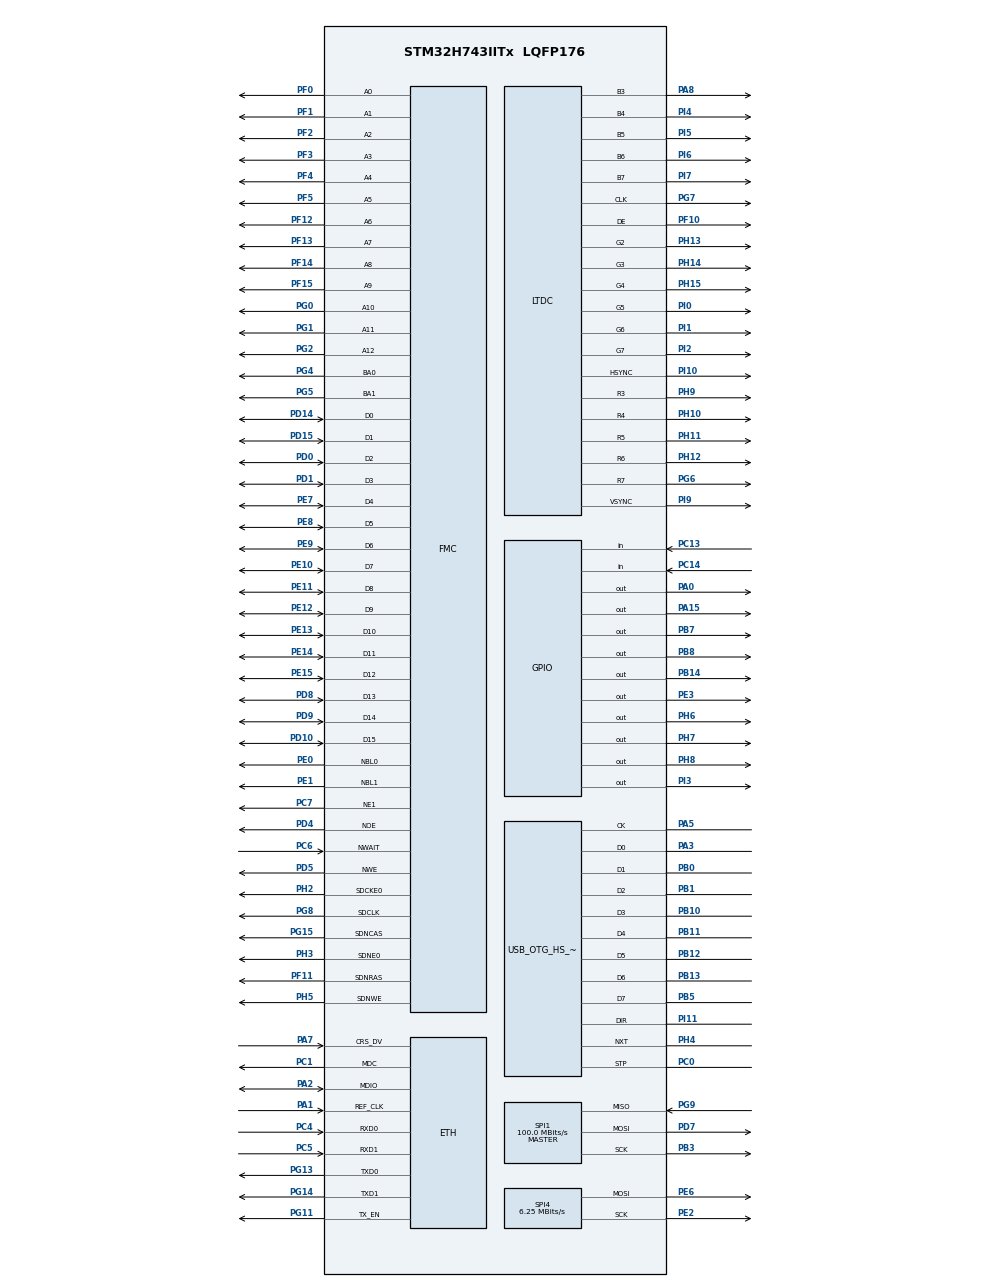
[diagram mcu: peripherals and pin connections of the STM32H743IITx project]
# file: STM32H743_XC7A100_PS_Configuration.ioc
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CORTEX_M7.AccessPermission_Spec=MPU_REGION_FULL_ACCESS
CORTEX_M7.BaseAddress_Spec=0xC0000000
CORTEX_M7.Enable_S-Cortex_Memory_Protection_Unit_Region1_Settings_S=__NULL
CORTEX_M7.IsBufferable_Spec=MPU_ACCESS_BUFFERABLE
CORTEX_M7.IsCacheable_Spec=MPU_ACCESS_CACHEABLE
CORTEX_M7.IsShareable_Spec=MPU_ACCESS_NOT_SHAREABLE
CORTEX_M7.Size_Spec=MPU_REGION_SIZE_4MB
CORTEX_M7.SubRegionDisable_Spec=0x0
CORTEX_M7.TypeExtField_Spec=MPU_TEX_LEVEL1
CORTEX_M7.default_mode_Activation=1
Dma.Request0=SPI4_TX
Dma.SPI4_TX.0.Direction=DMA_MEMORY_TO_PERIPH
Dma.SPI4_TX.0.EventEnable=DISABLE
Dma.SPI4_TX.0.FIFOMode=DMA_FIFOMODE_DISABLE
Dma.SPI4_TX.0.Instance=DMA1_Stream0
Dma.SPI4_TX.0.MemDataAlignment=DMA_MDATAALIGN_BYTE
Dma.SPI4_TX.0.MemInc=DMA_MINC_ENABLE
Dma.SPI4_TX.0.Mode=DMA_NORMAL
Dma.SPI4_TX.0.PeriphDataAlignment=DMA_PDATAALIGN_BYTE
Dma.SPI4_TX.0.PeriphInc=DMA_PINC_DISABLE
Dma.SPI4_TX.0.Polarity=HAL_DMAMUX_REQ_GEN_RISING
Dma.SPI4_TX.0.Priority=DMA_PRIORITY_LOW
Dma.SPI4_TX.0.RequestNumber=1
Dma.SPI4_TX.0.SignalID=NONE
Dma.SPI4_TX.0.SyncEnable=DISABLE
Dma.SPI4_TX.0.SyncPolarity=HAL_DMAMUX_SYNC_NO_EVENT
Dma.SPI4_TX.0.SyncRequestNumber=1
Dma.SPI4_TX.0.SyncSignalID=NONE
ETH.MediaInterface=HAL_ETH_RMII_MODE
FMC.CASLatency1=FMC_SDRAM_CAS_LATENCY_3
FMC.ColumnBitsNumber1=FMC_SDRAM_COLUMN_BITS_NUM_9
FMC.DataSetupTime1=10
FMC.ExitSelfRefreshDelay1=8
FMC.LoadToActiveDelay1=2
FMC.RCDDelay1=2
FMC.RPDelay1=2
FMC.ReadBurst1=FMC_SDRAM_RBURST_ENABLE
FMC.ReadPipeDelay1=FMC_SDRAM_RPIPE_DELAY_1
FMC.RowCycleDelay1=6
FMC.SDClockPeriod1=FMC_SDRAM_CLOCK_PERIOD_2
FMC.SelfRefreshTime1=6
FMC.WriteFifo1=FMC_WRITE_FIFO_DISABLE
FMC.WriteFifo2=FMC_WRITE_FIFO_DISABLE
FMC.WriteFifo3=FMC_WRITE_FIFO_DISABLE
FMC.WriteFifo4=FMC_WRITE_FIFO_DISABLE
FMC.WriteOperation1=FMC_WRITE_OPERATION_ENABLE
FMC.WriteRecoveryTime1=4
FREERTOS.Tasks01=FPGAConfigTask,0,2048,FPGAConfigDefaultTask,As weak,NULL,Dynamic,NULL,NULL;ewWinTask,-3,8192,ewWinDefaultTask,As weak,NULL,Dynamic,NULL,NULL;mousekeyTask,-3,1024,mousekeyDefaultTask,As weak,NULL,Dynamic,NULL,NULL;ETH,-3,2048,ETHDefaultTask,As weak,NULL,Dynamic,NULL,NULL
FREERTOS.configTOTAL_HEAP_SIZE=65535
LTDC.ActiveH=800
LTDC.ActiveW=480
LTDC.DEPolarity=LTDC_DEPOLARITY_AH
LTDC.HBP=1
LTDC.HFP=1
LTDC.HSPolarity=LTDC_HSPOLARITY_AH
LTDC.HSync=1
LTDC.PCPolarity=LTDC_PCPOLARITY_IIPC
LTDC.VBP=1
LTDC.VFP=1
LTDC.VSPolarity=LTDC_VSPOLARITY_AH
LTDC.VSync=1
LWIP.BSP.number=1
LWIP.GATEWAY_ADDRESS=192.168.100.001
LWIP.IP_ADDRESS=192.168.100.050
LWIP.LWIP_DHCP=0
LWIP.NETMASK_ADDRESS=255.255.255.000
LWIP.Version=v2.1.2_Cube
LWIP0.BSP.STBoard=false
LWIP0.BSP.api=BSP_COMPONENT_DRIVER
LWIP0.BSP.component=LAN8742
LWIP0.BSP.instance=LAN8742
LWIP0.BSP.name=Driver_PHY
LWIP0.BSP.semaphore=S_LAN8742
LWIP0.BSP.solution=LAN8742
Mcu.Family=STM32H7
Mcu.Name=STM32H743IITx
Mcu.Package=LQFP176
NVIC.DMA1_Stream0_IRQn=true\:5\:0\:false\:false\:true\:true\:false\:true\:true
NVIC.DMA2D_IRQn=true\:5\:0\:false\:false\:true\:true\:true\:true\:true
NVIC.LTDC_IRQn=true\:5\:0\:false\:false\:true\:true\:true\:true\:true
NVIC.OTG_HS_IRQn=true\:5\:0\:false\:false\:true\:true\:false\:true\:true
NVIC.PriorityGroup=NVIC_PRIORITYGROUP_4
NVIC.SPI4_IRQn=true\:5\:0\:false\:false\:true\:true\:false\:true\:true
PA0.Signal=GPIO_Output
PA1.GPIO_Speed=GPIO_SPEED_FREQ_VERY_HIGH
PA1.Mode=RMII
PA1.Signal=ETH_REF_CLK
PA13\ (JTMS/SWDIO).Mode=Serial_Wire
PA13\ (JTMS/SWDIO).Signal=DEBUG_JTMS-SWDIO
PA14\ (JTCK/SWCLK).Mode=Serial_Wire
PA14\ (JTCK/SWCLK).Signal=DEBUG_JTCK-SWCLK
PA15\ (JTDI).PinState=GPIO_PIN_SET
PA15\ (JTDI).Signal=GPIO_Output
PA2.GPIO_Speed=GPIO_SPEED_FREQ_VERY_HIGH
PA2.Mode=RMII
PA2.Signal=ETH_MDIO
PA3.Mode=Device_HS
PA3.Signal=USB_OTG_HS_ULPI_D0
PA5.Mode=Device_HS
PA5.Signal=USB_OTG_HS_ULPI_CK
PA7.GPIO_Speed=GPIO_SPEED_FREQ_VERY_HIGH
PA7.Mode=RMII
PA7.Signal=ETH_CRS_DV
PA8.GPIO_Speed=GPIO_SPEED_FREQ_VERY_HIGH
PA8.Mode=RGB565
PA8.Signal=LTDC_B3
PB0.Mode=Device_HS
PB0.Signal=USB_OTG_HS_ULPI_D1
PB1.Mode=Device_HS
PB1.Signal=USB_OTG_HS_ULPI_D2
PB10.Mode=Device_HS
PB10.Signal=USB_OTG_HS_ULPI_D3
PB11.Mode=Device_HS
PB11.Signal=USB_OTG_HS_ULPI_D4
PB12.Mode=Device_HS
PB12.Signal=USB_OTG_HS_ULPI_D5
PB13.Mode=Device_HS
PB13.Signal=USB_OTG_HS_ULPI_D6
PB14.Signal=GPIO_Output
PB3\ (JTDO/TRACESWO).Mode=Full_Duplex_Master
PB3\ (JTDO/TRACESWO).Signal=SPI1_SCK
PB5.Mode=Device_HS
PB5.Signal=USB_OTG_HS_ULPI_D7
PB7.GPIO_ModeDefaultOutputPP=GPIO_MODE_OUTPUT_OD
PB7.GPIO_PuPd=GPIO_NOPULL
PB7.Signal=GPIO_Output
PB8.GPIO_ModeDefaultOutputPP=GPIO_MODE_OUTPUT_OD
PB8.GPIO_PuPd=GPIO_NOPULL
PB8.Signal=GPIO_Output
PC0.Mode=Device_HS
PC0.Signal=USB_OTG_HS_ULPI_STP
PC1.GPIO_Speed=GPIO_SPEED_FREQ_VERY_HIGH
PC1.Mode=RMII
PC1.Signal=ETH_MDC
PC13.GPIO_PuPd=GPIO_PULLUP
PC13.Signal=GPIO_Input
PC14-OSC32_IN\ (OSC32_IN).GPIO_PuPd=GPIO_PULLUP
PC14-OSC32_IN\ (OSC32_IN).Signal=GPIO_Input
PC4.GPIO_Speed=GPIO_SPEED_FREQ_VERY_HIGH
PC4.Mode=RMII
PC4.Signal=ETH_RXD0
PC5.GPIO_Speed=GPIO_SPEED_FREQ_VERY_HIGH
PC5.Mode=RMII
PC5.Signal=ETH_RXD1
PC6.Signal=FMC_NWAIT
PC7.Mode=NorPsramChipSelect1_1
PC7.Signal=FMC_NE1
PD0.GPIO_PuPd=GPIO_PULLUP
PD0.Signal=FMC_D2_DA2
PD1.GPIO_PuPd=GPIO_PULLUP
PD1.Signal=FMC_D3_DA3
PD10.GPIO_PuPd=GPIO_PULLUP
PD10.Signal=FMC_D15_DA15
PD14.GPIO_PuPd=GPIO_PULLUP
PD14.Signal=FMC_D0_DA0
PD15.GPIO_PuPd=GPIO_PULLUP
PD15.Signal=FMC_D1_DA1
PD4.Signal=FMC_NOE
PD5.Signal=FMC_NWE
PD7.Mode=Full_Duplex_Master
PD7.Signal=SPI1_MOSI
PD8.GPIO_PuPd=GPIO_PULLUP
PD8.Signal=FMC_D13_DA13
PD9.GPIO_PuPd=GPIO_PULLUP
PD9.Signal=FMC_D14_DA14
PE0.GPIO_PuPd=GPIO_PULLUP
PE0.Signal=FMC_NBL0
PE1.GPIO_PuPd=GPIO_PULLUP
PE1.Signal=FMC_NBL1
PE10.GPIO_PuPd=GPIO_PULLUP
PE10.Signal=FMC_D7_DA7
PE11.GPIO_PuPd=GPIO_PULLUP
PE11.Signal=FMC_D8_DA8
PE12.GPIO_PuPd=GPIO_PULLUP
PE12.Signal=FMC_D9_DA9
PE13.GPIO_PuPd=GPIO_PULLUP
PE13.Signal=FMC_D10_DA10
PE14.GPIO_PuPd=GPIO_PULLUP
PE14.Signal=FMC_D11_DA11
PE15.GPIO_PuPd=GPIO_PULLUP
PE15.Signal=FMC_D12_DA12
PE2.GPIO_Speed=GPIO_SPEED_FREQ_HIGH
PE2.Mode=TX_Only_Simplex_Unidirect_Master
PE2.Signal=SPI4_SCK
PE3.Signal=GPIO_Output
PE6.GPIO_Speed=GPIO_SPEED_FREQ_HIGH
PE6.Mode=TX_Only_Simplex_Unidirect_Master
PE6.Signal=SPI4_MOSI
PE7.GPIO_PuPd=GPIO_PULLUP
PE7.Signal=FMC_D4_DA4
PE8.GPIO_PuPd=GPIO_PULLUP
PE8.Signal=FMC_D5_DA5
PE9.GPIO_PuPd=GPIO_PULLUP
PE9.Signal=FMC_D6_DA6
PF0.GPIO_PuPd=GPIO_PULLUP
PF0.Signal=FMC_A0
PF1.GPIO_PuPd=GPIO_PULLUP
PF1.Signal=FMC_A1
PF10.GPIO_Speed=GPIO_SPEED_FREQ_VERY_HIGH
PF10.Mode=RGB565
PF10.Signal=LTDC_DE
PF11.GPIO_PuPd=GPIO_PULLUP
PF11.Signal=FMC_SDNRAS
PF12.GPIO_PuPd=GPIO_PULLUP
PF12.Signal=FMC_A6
PF13.GPIO_PuPd=GPIO_PULLUP
PF13.Signal=FMC_A7
PF14.GPIO_PuPd=GPIO_PULLUP
PF14.Signal=FMC_A8
PF15.GPIO_PuPd=GPIO_PULLUP
PF15.Signal=FMC_A9
PF2.GPIO_PuPd=GPIO_PULLUP
PF2.Signal=FMC_A2
PF3.GPIO_PuPd=GPIO_PULLUP
PF3.Signal=FMC_A3
PF4.GPIO_PuPd=GPIO_PULLUP
PF4.Signal=FMC_A4
PF5.GPIO_PuPd=GPIO_PULLUP
PF5.Signal=FMC_A5
PG0.GPIO_PuPd=GPIO_PULLUP
PG0.Signal=FMC_A10
PG1.GPIO_PuPd=GPIO_PULLUP
PG1.Signal=FMC_A11
PG11.GPIO_Speed=GPIO_SPEED_FREQ_VERY_HIGH
PG11.Mode=RMII
PG11.Signal=ETH_TX_EN
PG13.GPIO_Speed=GPIO_SPEED_FREQ_VERY_HIGH
PG13.Mode=RMII
PG13.Signal=ETH_TXD0
PG14.GPIO_Speed=GPIO_SPEED_FREQ_VERY_HIGH
PG14.Mode=RMII
PG14.Signal=ETH_TXD1
PG15.GPIO_PuPd=GPIO_PULLUP
PG15.Signal=FMC_SDNCAS
PG2.GPIO_PuPd=GPIO_PULLUP
PG2.Signal=FMC_A12
PG4.GPIO_PuPd=GPIO_PULLUP
PG4.Signal=FMC_A14_BA0
PG5.GPIO_PuPd=GPIO_PULLUP
PG5.Signal=FMC_A15_BA1
PG6.GPIO_Speed=GPIO_SPEED_FREQ_VERY_HIGH
PG6.Mode=RGB565
PG6.Signal=LTDC_R7
PG7.GPIO_Speed=GPIO_SPEED_FREQ_VERY_HIGH
PG7.Mode=RGB565
PG7.Signal=LTDC_CLK
PG8.GPIO_PuPd=GPIO_PULLUP
PG8.Signal=FMC_SDCLK
PG9.Mode=Full_Duplex_Master
PG9.Signal=SPI1_MISO
PH0-OSC_IN\ (PH0).Mode=HSE-External-Clock-Source
PH0-OSC_IN\ (PH0).Signal=RCC_OSC_IN
PH10.GPIO_Speed=GPIO_SPEED_FREQ_VERY_HIGH
PH10.Mode=RGB565
PH10.Signal=LTDC_R4
PH11.GPIO_Speed=GPIO_SPEED_FREQ_VERY_HIGH
PH11.Mode=RGB565
PH11.Signal=LTDC_R5
PH12.GPIO_Speed=GPIO_SPEED_FREQ_VERY_HIGH
PH12.Mode=RGB565
PH12.Signal=LTDC_R6
PH13.GPIO_Speed=GPIO_SPEED_FREQ_VERY_HIGH
PH13.Mode=RGB565
PH13.Signal=LTDC_G2
PH14.GPIO_Speed=GPIO_SPEED_FREQ_VERY_HIGH
PH14.Mode=RGB565
PH14.Signal=LTDC_G3
PH15.GPIO_Speed=GPIO_SPEED_FREQ_VERY_HIGH
PH15.Mode=RGB565
PH15.Signal=LTDC_G4
PH2.GPIO_PuPd=GPIO_PULLUP
PH2.Mode=SdramChipSelect1_1
PH2.Signal=FMC_SDCKE0
PH3.GPIO_PuPd=GPIO_PULLUP
PH3.Mode=SdramChipSelect1_1
PH3.Signal=FMC_SDNE0
PH4.Mode=Device_HS
PH4.Signal=USB_OTG_HS_ULPI_NXT
PH5.GPIO_PuPd=GPIO_PULLUP
PH5.Signal=FMC_SDNWE
PH6.GPIO_Speed=GPIO_SPEED_FREQ_VERY_HIGH
PH6.Signal=GPIO_Output
PH7.GPIO_Speed=GPIO_SPEED_FREQ_VERY_HIGH
PH7.Signal=GPIO_Output
PH8.GPIO_Speed=GPIO_SPEED_FREQ_VERY_HIGH
PH8.Signal=GPIO_Output
PH9.GPIO_Speed=GPIO_SPEED_FREQ_VERY_HIGH
PH9.Mode=RGB565
PH9.Signal=LTDC_R3
PI0.GPIO_Speed=GPIO_SPEED_FREQ_VERY_HIGH
PI0.Mode=RGB565
PI0.Signal=LTDC_G5
PI1.GPIO_Speed=GPIO_SPEED_FREQ_VERY_HIGH
PI1.Mode=RGB565
PI1.Signal=LTDC_G6
PI10.GPIO_Speed=GPIO_SPEED_FREQ_VERY_HIGH
PI10.Mode=RGB565
PI10.Signal=LTDC_HSYNC
PI11.Mode=Device_HS
PI11.Signal=USB_OTG_HS_ULPI_DIR
PI2.GPIO_Speed=GPIO_SPEED_FREQ_VERY_HIGH
PI2.Mode=RGB565
PI2.Signal=LTDC_G7
PI3.PinState=GPIO_PIN_SET
PI3.Signal=GPIO_Output
PI4.GPIO_Speed=GPIO_SPEED_FREQ_VERY_HIGH
PI4.Mode=RGB565
PI4.Signal=LTDC_B4
PI5.GPIO_Speed=GPIO_SPEED_FREQ_VERY_HIGH
PI5.Mode=RGB565
PI5.Signal=LTDC_B5
PI6.GPIO_Speed=GPIO_SPEED_FREQ_VERY_HIGH
PI6.Mode=RGB565
PI6.Signal=LTDC_B6
PI7.GPIO_Speed=GPIO_SPEED_FREQ_VERY_HIGH
PI7.Mode=RGB565
PI7.Signal=LTDC_B7
PI9.GPIO_Speed=GPIO_SPEED_FREQ_VERY_HIGH
PI9.Mode=RGB565
PI9.Signal=LTDC_VSYNC
ProjectManager.HeapSize=0x200
ProjectManager.StackSize=0x400
ProjectManager.TargetToolchain=MDK-ARM V5.32
RCC.ADCFreq_Value=200000000
RCC.APB1Freq_Value=100000000
RCC.APB2Freq_Value=100000000
RCC.APB3Freq_Value=100000000
RCC.APB4Freq_Value=100000000
RCC.CortexFreq_Value=400000000
RCC.D1PPRE=RCC_APB3_DIV2
RCC.D2PPRE1=RCC_APB1_DIV2
RCC.D2PPRE2=RCC_APB2_DIV2
RCC.D3PPRE=RCC_APB4_DIV2
RCC.DIVM1=5
RCC.DIVM2=5
RCC.DIVM3=5
RCC.DIVN1=160
RCC.DIVN2=80
RCC.DIVN3=88
RCC.DIVQ1=4
RCC.DIVQ3=4
RCC.DIVR3=18
RCC.FMCCLockSelection=RCC_FMCCLKSOURCE_PLL
RCC.HCLKFreq_Value=200000000
RCC.HPRE=RCC_HCLK_DIV2
RCC.PLL2FRACN=0
RCC.PLL3FRACN=0
RCC.PLLFRACN=0
RCC.PLLSourceVirtual=RCC_PLLSOURCE_HSE
RCC.SYSCLKFreq_VALUE=400000000
RCC.SYSCLKSource=RCC_SYSCLKSOURCE_PLLCLK
RCC.USBCLockSelection=RCC_USBCLKSOURCE_HSI48
RCC.USBFreq_Value=48000000
SH.FMC_A0.0=FMC_A0,13b-sda1
SH.FMC_A0.1=FMC_A0,1b-a1
SH.FMC_A1.0=FMC_A1,13b-sda1
SH.FMC_A10.0=FMC_A10,13b-sda1
SH.FMC_A11.0=FMC_A11,13b-sda1
SH.FMC_A12.0=FMC_A12,13b-sda1
SH.FMC_A14_BA0.0=FMC_BA0,FourSdramBanks1
SH.FMC_A15_BA1.0=FMC_BA1,FourSdramBanks1
SH.FMC_A2.0=FMC_A2,13b-sda1
SH.FMC_A3.0=FMC_A3,13b-sda1
SH.FMC_A4.0=FMC_A4,13b-sda1
SH.FMC_A5.0=FMC_A5,13b-sda1
SH.FMC_A6.0=FMC_A6,13b-sda1
SH.FMC_A7.0=FMC_A7,13b-sda1
SH.FMC_A8.0=FMC_A8,13b-sda1
SH.FMC_A9.0=FMC_A9,13b-sda1
SH.FMC_D0_DA0.0=FMC_D0,sd-16b-d1
SH.FMC_D0_DA0.1=FMC_D0,16b-d1
SH.FMC_D10_DA10.0=FMC_D10,sd-16b-d1
SH.FMC_D10_DA10.1=FMC_D10,16b-d1
SH.FMC_D11_DA11.0=FMC_D11,sd-16b-d1
SH.FMC_D11_DA11.1=FMC_D11,16b-d1
SH.FMC_D12_DA12.0=FMC_D12,sd-16b-d1
SH.FMC_D12_DA12.1=FMC_D12,16b-d1
SH.FMC_D13_DA13.0=FMC_D13,sd-16b-d1
SH.FMC_D13_DA13.1=FMC_D13,16b-d1
SH.FMC_D14_DA14.0=FMC_D14,sd-16b-d1
SH.FMC_D14_DA14.1=FMC_D14,16b-d1
SH.FMC_D15_DA15.0=FMC_D15,sd-16b-d1
SH.FMC_D15_DA15.1=FMC_D15,16b-d1
SH.FMC_D1_DA1.0=FMC_D1,sd-16b-d1
SH.FMC_D1_DA1.1=FMC_D1,16b-d1
SH.FMC_D2_DA2.0=FMC_D2,sd-16b-d1
SH.FMC_D2_DA2.1=FMC_D2,16b-d1
SH.FMC_D3_DA3.0=FMC_D3,sd-16b-d1
SH.FMC_D3_DA3.1=FMC_D3,16b-d1
SH.FMC_D4_DA4.0=FMC_D4,sd-16b-d1
SH.FMC_D4_DA4.1=FMC_D4,16b-d1
SH.FMC_D5_DA5.0=FMC_D5,sd-16b-d1
SH.FMC_D5_DA5.1=FMC_D5,16b-d1
SH.FMC_D6_DA6.0=FMC_D6,sd-16b-d1
SH.FMC_D6_DA6.1=FMC_D6,16b-d1
SH.FMC_D7_DA7.0=FMC_D7,sd-16b-d1
SH.FMC_D7_DA7.1=FMC_D7,16b-d1
SH.FMC_D8_DA8.0=FMC_D8,sd-16b-d1
SH.FMC_D8_DA8.1=FMC_D8,16b-d1
SH.FMC_D9_DA9.0=FMC_D9,sd-16b-d1
SH.FMC_D9_DA9.1=FMC_D9,16b-d1
SH.FMC_NBL0.0=FMC_NBL0,Sd2ByteEnable1
SH.FMC_NBL1.0=FMC_NBL1,Sd2ByteEnable1
SH.FMC_NOE.0=FMC_NOE,Sram1
SH.FMC_NWAIT.0=FMC_NWAIT,AsynchronousWait1
SH.FMC_NWE.0=FMC_NWE,Sram1
SH.FMC_SDCLK.0=FMC_SDCLK,13b-sda1
SH.FMC_SDNCAS.0=FMC_SDNCAS,13b-sda1
SH.FMC_SDNRAS.0=FMC_SDNRAS,13b-sda1
SH.FMC_SDNWE.0=FMC_SDNWE,13b-sda1
SPI1.CalculateBaudRate=100.0 MBits/s
SPI1.Direction=SPI_DIRECTION_2LINES
SPI1.Mode=SPI_MODE_MASTER
SPI1.VirtualType=VM_MASTER
SPI4.BaudRatePrescaler=SPI_BAUDRATEPRESCALER_16
SPI4.CLKPhase=SPI_PHASE_2EDGE
SPI4.CLKPolarity=SPI_POLARITY_HIGH
SPI4.CalculateBaudRate=6.25 MBits/s
SPI4.DataSize=SPI_DATASIZE_8BIT
SPI4.Direction=SPI_DIRECTION_2LINES_TXONLY
SPI4.Mode=SPI_MODE_MASTER
SPI4.NSSPMode=SPI_NSS_PULSE_DISABLE
SPI4.VirtualType=VM_MASTER
USB_DEVICE.CLASS_NAME_HS=CDC
USB_DEVICE.VirtualMode-CDC_HS=Cdc
USB_DEVICE.VirtualModeHS=Cdc_HS
USB_OTG_HS.VirtualMode-Device_HS=Device_HS
VP_DMA2D_VS_DMA2D.Mode=DMA2D_Activate
VP_FREERTOS_VS_CMSIS_V1.Mode=CMSIS_V1
VP_LWIP_VS_Enabled.Mode=Enabled
VP_MEMORYMAP_VS_MEMORYMAP.Mode=CurAppReg
VP_USB_DEVICE_VS_USB_DEVICE_CDC_HS.Mode=CDC_HS
board=custom

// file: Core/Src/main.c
/* USER CODE BEGIN Header */
/**
  ******************************************************************************
  * @file           : main.c
  * @brief          : Main program body
  ******************************************************************************
  * @attention
  *
  * Copyright (c) 2026 STMicroelectronics.
  * All rights reserved.
  *
  * This software is licensed under terms that can be found in the LICENSE file
  * in the root directory of this software component.
  * If no LICENSE file comes with this software, it is provided AS-IS.
  *
  ******************************************************************************
  */
/* USER CODE END Header */
#include "main.h"
#include "cmsis_os.h"
#include "dma.h"
#include "dma2d.h"
#include "ltdc.h"
#include "lwip.h"
#include "memorymap.h"
#include "spi.h"
#include "usb_device.h"
#include "gpio.h"
#include "fmc.h"

/* USER CODE BEGIN Includes */
#include "sdram.h"
#include "bsp_lcd_rgb.h"
#include "bsp_dwt.h"
#include "bsp_led.h"

extern volatile uint8_t g_sdram_ready;
/* USER CODE END Includes */

/* USER CODE BEGIN PD */
#define CONFIGURATION_MODE 0  //1-Slave Serial 0-JTAG
#define UI_EARLY_LCD_DIAG 0U
#define LATTICE_SINGLE_WIRE_TEST 0U
/* USER CODE END PD */

/* USER CODE BEGIN PV */
volatile uint8_t test = 0U;

/* USER CODE END PV */

void SystemClock_Config(void);
static void MPU_Config(void);
void MX_FREERTOS_Init(void);
/* USER CODE BEGIN PFP */
static void CPU_CACHE_Enable(void);
static void UI_CustomPlatformInit(void);
static void LatticeSingleWireTestInit(void);
static void LatticeSingleWireTestRun(void);

/* USER CODE END PFP */

/* USER CODE BEGIN 0 */

static void UI_EarlyFramebufferInit(void)
{
  uint32_t i;
  uint16_t *p_logic = (uint16_t *)0xC0000000U;
  uint16_t *p0 = (uint16_t *)0xC0200000U;
  uint16_t *p1 = (uint16_t *)0xC0300000U;
  const uint32_t logic_pixels = 2U * 800U * 480U;
  const uint32_t phys_pixels  = 480U * 800U;

  for (i = 0U; i < logic_pixels; i++)
  {
    p_logic[i] = 0U;
  }

  for (i = 0U; i < phys_pixels; i++)
  {
    p0[i] = 0U;
    p1[i] = 0U;
  }

  SCB_CleanDCache_by_Addr((uint32_t *)0xC0000000U, logic_pixels * 2U);
  SCB_CleanDCache_by_Addr((uint32_t *)0xC0200000U, phys_pixels * 2U);
  SCB_CleanDCache_by_Addr((uint32_t *)0xC0300000U, phys_pixels * 2U);
}

static void UI_CustomPlatformInit(void)
{
  /* FMC base init is generated by CubeMX; SDRAM command sequence is not. */
  SDRAM_Init_Sequence();
  g_sdram_ready = 1U;
}

static void LatticeSingleWireTestInit(void)
{
  GPIO_InitTypeDef GPIO_InitStruct = {0};

  HAL_GPIO_WritePin(GPIOB, GPIO_PIN_3, GPIO_PIN_RESET);

  GPIO_InitStruct.Pin = GPIO_PIN_3;
  GPIO_InitStruct.Mode = GPIO_MODE_OUTPUT_PP;
  GPIO_InitStruct.Pull = GPIO_NOPULL;
  GPIO_InitStruct.Speed = GPIO_SPEED_FREQ_LOW;
  HAL_GPIO_Init(GPIOB, &GPIO_InitStruct);

  GPIO_InitStruct.Pin = GPIO_PIN_9;
  GPIO_InitStruct.Mode = GPIO_MODE_INPUT;
  GPIO_InitStruct.Pull = GPIO_NOPULL;
  HAL_GPIO_Init(GPIOG, &GPIO_InitStruct);

  test = (uint8_t)HAL_GPIO_ReadPin(GPIOG, GPIO_PIN_9);
}

static void LatticeSingleWireTestRun(void)
{
  for (;;)
  {
    test = (uint8_t)HAL_GPIO_ReadPin(GPIOG, GPIO_PIN_9);
    HAL_Delay(1);
  }
}

/* USER CODE END 0 */

int main(void)
{

  /* MPU Configuration--------------------------------------------------------*/
  MPU_Config();

  /* MCU Configuration--------------------------------------------------------*/

  /* Reset of all peripherals, Initializes the Flash interface and the Systick. */
  HAL_Init();

  /* USER CODE BEGIN Init */
  CPU_CACHE_Enable();

  /* USER CODE END Init */

  /* Configure the system clock */
  SystemClock_Config();

  /* Initialize all configured peripherals */
  MX_GPIO_Init();
  MX_DMA_Init();
  MX_FMC_Init();
  MX_SPI4_Init();
  MX_DMA2D_Init();
  MX_LTDC_Init();
  MX_SPI1_Init();
  /* USER CODE BEGIN 2 */
  UI_CustomPlatformInit();
#if (UI_EARLY_LCD_DIAG == 1U)
//  UI_EarlyFramebufferInit();
//  LCD_RGB_Init();
//  if (LTDC_Layer1->CFBAR != 0xC0200000U)
//  {
//    LTDC_Layer1->CFBAR = 0xC0200000U;
//    LTDC->SRCR = LTDC_SRCR_IMR;
//  }
//  LCD_RGB_BacklightOn();
//  LCD_RGB_Fill(0xFFFFU);
//  bsp_LedOn(4);
  for (;;)
  {
		HAL_GPIO_TogglePin(GPIOA,GPIO_PIN_0);
    HAL_Delay(500);
  }
#endif

  /* USER CODE END 2 */

  /* Call init function for freertos objects (in cmsis_os2.c) */
  MX_FREERTOS_Init();

  /* Start scheduler */
  osKernelStart();

  /* We should never get here as control is now taken by the scheduler */

  /* Infinite loop */
  while (1)
  {

  }
}

void SystemClock_Config(void)
{
  RCC_OscInitTypeDef RCC_OscInitStruct = {0};
  RCC_ClkInitTypeDef RCC_ClkInitStruct = {0};

  /** Supply configuration update enable
  */
  HAL_PWREx_ConfigSupply(PWR_LDO_SUPPLY);

  /** Configure the main internal regulator output voltage
  */
  __HAL_PWR_VOLTAGESCALING_CONFIG(PWR_REGULATOR_VOLTAGE_SCALE1);

  while(!__HAL_PWR_GET_FLAG(PWR_FLAG_VOSRDY)) {}

  /** Initializes the RCC Oscillators according to the specified parameters
  * in the RCC_OscInitTypeDef structure.
  */
  RCC_OscInitStruct.OscillatorType = RCC_OSCILLATORTYPE_HSI48|RCC_OSCILLATORTYPE_HSE;
  RCC_OscInitStruct.HSEState = RCC_HSE_BYPASS;
  RCC_OscInitStruct.HSI48State = RCC_HSI48_ON;
  RCC_OscInitStruct.PLL.PLLState = RCC_PLL_ON;
  RCC_OscInitStruct.PLL.PLLSource = RCC_PLLSOURCE_HSE;
  RCC_OscInitStruct.PLL.PLLM = 5;
  RCC_OscInitStruct.PLL.PLLN = 160;
  RCC_OscInitStruct.PLL.PLLP = 2;
  RCC_OscInitStruct.PLL.PLLQ = 4;
  RCC_OscInitStruct.PLL.PLLR = 2;
  RCC_OscInitStruct.PLL.PLLRGE = RCC_PLL1VCIRANGE_2;
  RCC_OscInitStruct.PLL.PLLVCOSEL = RCC_PLL1VCOWIDE;
  RCC_OscInitStruct.PLL.PLLFRACN = 0;
  if (HAL_RCC_OscConfig(&RCC_OscInitStruct) != HAL_OK)
  {
    Error_Handler();
  }

  /** Initializes the CPU, AHB and APB buses clocks
  */
  RCC_ClkInitStruct.ClockType = RCC_CLOCKTYPE_HCLK|RCC_CLOCKTYPE_SYSCLK
                              |RCC_CLOCKTYPE_PCLK1|RCC_CLOCKTYPE_PCLK2
                              |RCC_CLOCKTYPE_D3PCLK1|RCC_CLOCKTYPE_D1PCLK1;
  RCC_ClkInitStruct.SYSCLKSource = RCC_SYSCLKSOURCE_PLLCLK;
  RCC_ClkInitStruct.SYSCLKDivider = RCC_SYSCLK_DIV1;
  RCC_ClkInitStruct.AHBCLKDivider = RCC_HCLK_DIV2;
  RCC_ClkInitStruct.APB3CLKDivider = RCC_APB3_DIV2;
  RCC_ClkInitStruct.APB1CLKDivider = RCC_APB1_DIV2;
  RCC_ClkInitStruct.APB2CLKDivider = RCC_APB2_DIV2;
  RCC_ClkInitStruct.APB4CLKDivider = RCC_APB4_DIV2;

  if (HAL_RCC_ClockConfig(&RCC_ClkInitStruct, FLASH_LATENCY_2) != HAL_OK)
  {
    Error_Handler();
  }
}

/* USER CODE BEGIN 4 */
static void CPU_CACHE_Enable(void)
{
  SCB_EnableICache();
  SCB_EnableDCache();
  SCB->CCR &= ~(uint32_t)SCB_CCR_UNALIGN_TRP_Msk;
  __DSB();
  __ISB();
}
/* USER CODE END 4 */

 /* MPU Configuration */

void MPU_Config(void)
{
  MPU_Region_InitTypeDef MPU_InitStruct = {0};

  /* Disables the MPU */
  HAL_MPU_Disable();

  /** Initializes and configures the Region and the memory to be protected
  */
  MPU_InitStruct.Enable = MPU_REGION_ENABLE;
  MPU_InitStruct.Number = MPU_REGION_NUMBER0;
  MPU_InitStruct.BaseAddress = 0xC0000000;
  MPU_InitStruct.Size = MPU_REGION_SIZE_4MB;
  MPU_InitStruct.SubRegionDisable = 0x0;
  MPU_InitStruct.TypeExtField = MPU_TEX_LEVEL1;
  MPU_InitStruct.AccessPermission = MPU_REGION_FULL_ACCESS;
  MPU_InitStruct.DisableExec = MPU_INSTRUCTION_ACCESS_DISABLE;
  MPU_InitStruct.IsShareable = MPU_ACCESS_NOT_SHAREABLE;
  MPU_InitStruct.IsCacheable = MPU_ACCESS_CACHEABLE;
  MPU_InitStruct.IsBufferable = MPU_ACCESS_BUFFERABLE;

  HAL_MPU_ConfigRegion(&MPU_InitStruct);
  /* Enables the MPU */
  HAL_MPU_Enable(MPU_PRIVILEGED_DEFAULT);

}

void Error_Handler(void)
{
  __disable_irq();
  while (1)
  {
  }
}

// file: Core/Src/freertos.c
/* USER CODE BEGIN Header */
/**
  ******************************************************************************
  * File Name          : freertos.c
  * Description        : Code for freertos applications
  ******************************************************************************
  * @attention
  *
  * Copyright (c) 2026 STMicroelectronics.
  * All rights reserved.
  *
  * This software is licensed under terms that can be found in the LICENSE file
  * in the root directory of this software component.
  * If no LICENSE file comes with this software, it is provided AS-IS.
  *
  ******************************************************************************
  */
/* USER CODE END Header */

#include "FreeRTOS.h"
#include "task.h"
#include "main.h"
#include "cmsis_os.h"

/* USER CODE BEGIN Includes */
#include "ewWinDefaultTask.h"
/* USER CODE END Includes */

osThreadId FPGAConfigTaskHandle;
osThreadId ewWinTaskHandle;
osThreadId mousekeyTaskHandle;
osThreadId ETHHandle;

void FPGAConfigDefaultTask(void const * argument);
void ewWinDefaultTask(void const * argument);
void mousekeyDefaultTask(void const * argument);
void ETHDefaultTask(void const * argument);

extern void MX_USB_DEVICE_Init(void);
extern void MX_LWIP_Init(void);
void MX_FREERTOS_Init(void); /* (MISRA C 2004 rule 8.1) */

/* GetIdleTaskMemory prototype (linked to static allocation support) */
void vApplicationGetIdleTaskMemory( StaticTask_t **ppxIdleTaskTCBBuffer, StackType_t **ppxIdleTaskStackBuffer, uint32_t *pulIdleTaskStackSize );

/* USER CODE BEGIN GET_IDLE_TASK_MEMORY */
static StaticTask_t xIdleTaskTCBBuffer;
static StackType_t xIdleStack[configMINIMAL_STACK_SIZE];

void vApplicationGetIdleTaskMemory( StaticTask_t **ppxIdleTaskTCBBuffer, StackType_t **ppxIdleTaskStackBuffer, uint32_t *pulIdleTaskStackSize )
{
  *ppxIdleTaskTCBBuffer = &xIdleTaskTCBBuffer;
  *ppxIdleTaskStackBuffer = &xIdleStack[0];
  *pulIdleTaskStackSize = configMINIMAL_STACK_SIZE;
  /* place for user code */
}
/* USER CODE END GET_IDLE_TASK_MEMORY */

void MX_FREERTOS_Init(void) {

  /* Create the thread(s) */
  /* definition and creation of FPGAConfigTask */
  osThreadDef(FPGAConfigTask, FPGAConfigDefaultTask, osPriorityNormal, 0, 2048);
  FPGAConfigTaskHandle = osThreadCreate(osThread(FPGAConfigTask), NULL);

  /* definition and creation of ewWinTask */
  osThreadDef(ewWinTask, ewWinDefaultTask, osPriorityIdle, 0, 8192);
  ewWinTaskHandle = osThreadCreate(osThread(ewWinTask), NULL);

  /* definition and creation of mousekeyTask */
  osThreadDef(mousekeyTask, mousekeyDefaultTask, osPriorityIdle, 0, 1024);
  mousekeyTaskHandle = osThreadCreate(osThread(mousekeyTask), NULL);

  /* definition and creation of ETH */
  osThreadDef(ETH, ETHDefaultTask, osPriorityIdle, 0, 2048);
  ETHHandle = osThreadCreate(osThread(ETH), NULL);

  /* USER CODE BEGIN RTOS_THREADS */
  if (ewWinTaskHandle != NULL)
  {
    osThreadSetPriority(ewWinTaskHandle, osPriorityAboveNormal);
  }
  /* USER CODE END RTOS_THREADS */

}

__weak void FPGAConfigDefaultTask(void const * argument)
{
  /* init code for USB_DEVICE */
  MX_USB_DEVICE_Init();

  /* init code for LWIP */
  MX_LWIP_Init();
  for(;;)
  {
    osDelay(1);
  }
}

__weak void ewWinDefaultTask(void const * argument)
{
  for(;;)
  {
    osDelay(1);
  }
}

__weak void mousekeyDefaultTask(void const * argument)
{
  for(;;)
  {
    osDelay(1);
  }
}

__weak void ETHDefaultTask(void const * argument)
{
  for(;;)
  {
    osDelay(1);
  }
}
